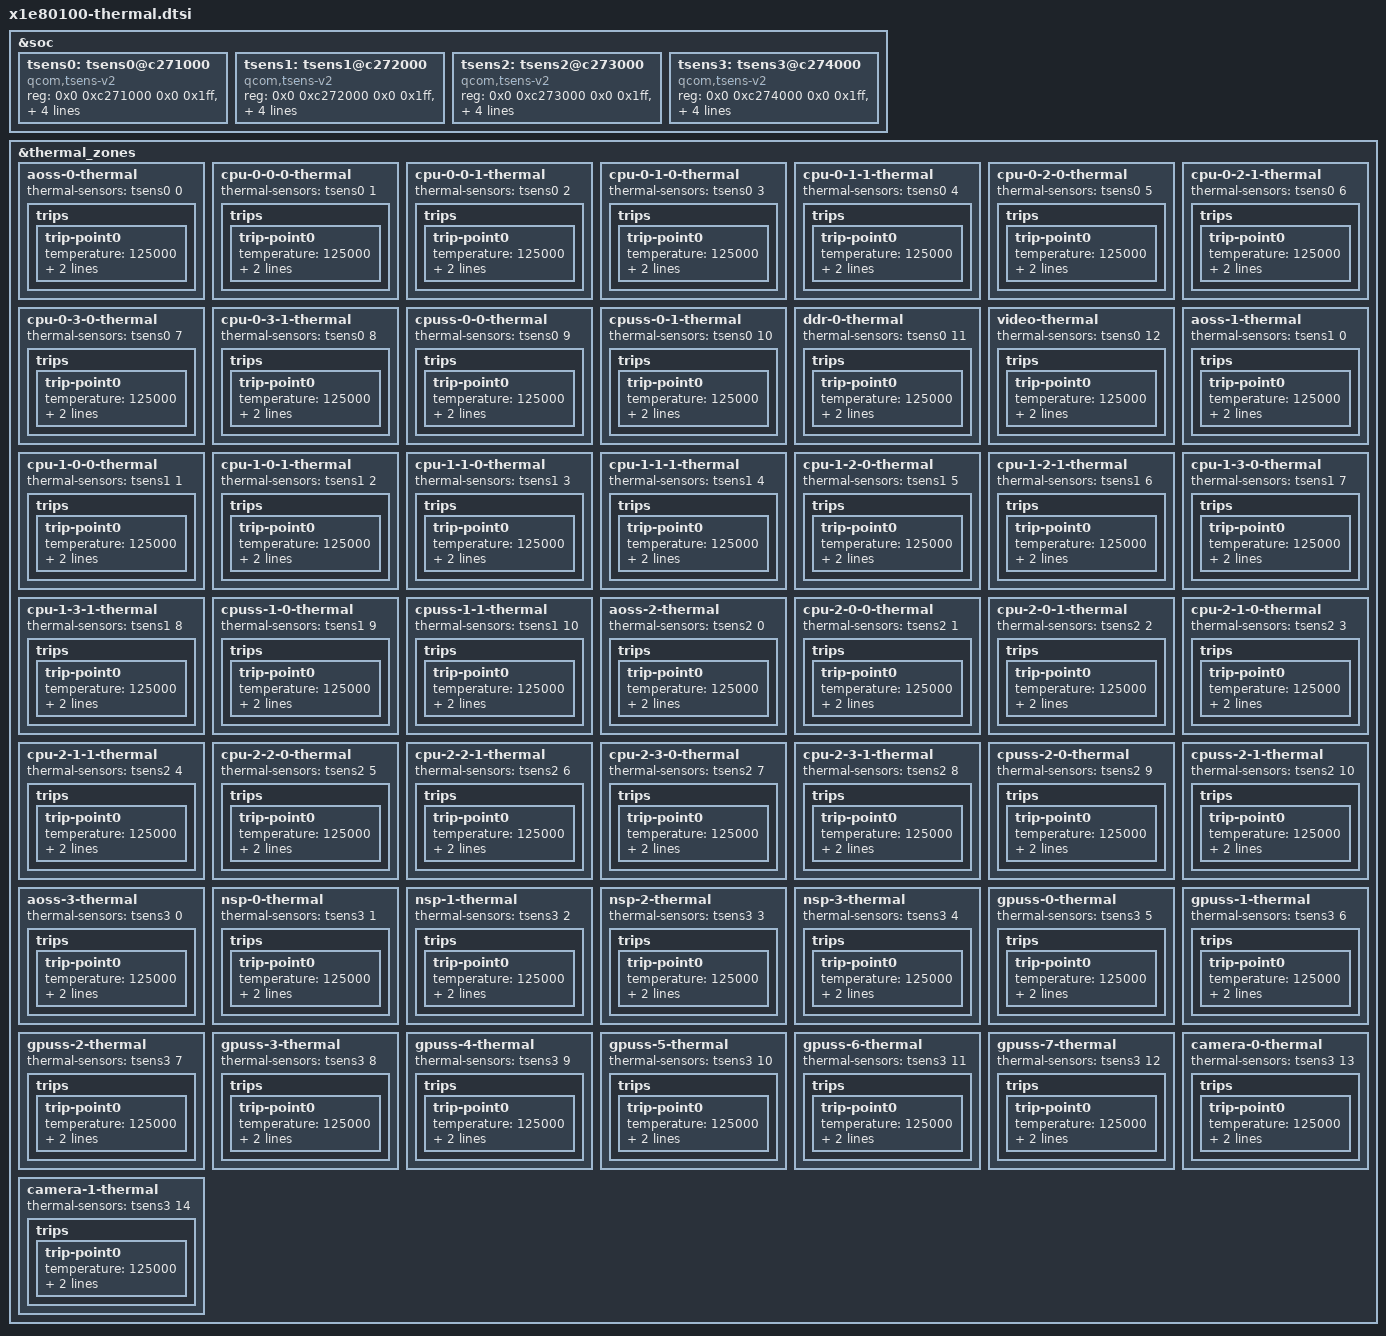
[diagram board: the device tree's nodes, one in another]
// SPDX-License-Identifier: BSD-3-Clause
/*
 * Copyright (c) Qualcomm Technologies, Inc. and/or its subsidiaries.
 */

#include <dt-bindings/thermal/thermal_qti.h>

&soc {
	tsens0: tsens0@c271000 {
		compatible = "qcom,tsens-v2";
		reg = <0x0 0xc271000 0x0 0x1ff>, /* TM */
				<0x0 0xc222000 0x0 0x1ff>; /* SROT */
		#qcom,sensors = <13>;
		interrupts = <GIC_SPI 506 IRQ_TYPE_LEVEL_HIGH>,
				<GIC_SPI 641 IRQ_TYPE_LEVEL_HIGH>;
		interrupt-names = "uplow","critical";
		#thermal-sensor-cells = <1>;
	};

	tsens1: tsens1@c272000 {
		compatible = "qcom,tsens-v2";
		reg = <0x0 0xc272000 0x0 0x1ff>, /* TM */
				<0x0 0xc223000 0x0 0x1ff>; /* SROT */
		#qcom,sensors = <11>;
		interrupts = <GIC_SPI 507 IRQ_TYPE_LEVEL_HIGH>,
				<GIC_SPI 642 IRQ_TYPE_LEVEL_HIGH>;
		interrupt-names = "uplow","critical";
		#thermal-sensor-cells = <1>;
	};

	tsens2: tsens2@c273000 {
		compatible = "qcom,tsens-v2";
		reg = <0x0 0xc273000 0x0 0x1ff>, /* TM */
				<0x0 0xc224000 0x0 0x1ff>; /* SROT */
		#qcom,sensors = <11>;
		interrupts = <GIC_SPI 508 IRQ_TYPE_LEVEL_HIGH>,
				<GIC_SPI 643 IRQ_TYPE_LEVEL_HIGH>;
		interrupt-names = "uplow","critical";
		#thermal-sensor-cells = <1>;
	};

	tsens3: tsens3@c274000 {
		compatible = "qcom,tsens-v2";
		reg = <0x0 0xc274000 0x0 0x1ff>, /* TM */
				<0x0 0xc225000 0x0 0x1ff>; /* SROT */
		#qcom,sensors = <15>;
		interrupts = <GIC_SPI 509 IRQ_TYPE_LEVEL_HIGH>,
				<GIC_SPI 644 IRQ_TYPE_LEVEL_HIGH>;
		interrupt-names = "uplow","critical";
		#thermal-sensor-cells = <1>;
	};
};

&thermal_zones {
	aoss-0-thermal {
		thermal-sensors = <&tsens0 0>;
		trips {
			trip-point0 {
				temperature = <125000>;
				hysteresis = <5000>;
				type = "passive";
			};
		};
	};

	cpu-0-0-0-thermal {
		thermal-sensors = <&tsens0 1>;
		trips {
			trip-point0 {
				temperature = <125000>;
				hysteresis = <5000>;
				type = "passive";
			};
		};
	};

	cpu-0-0-1-thermal {
		thermal-sensors = <&tsens0 2>;
		trips {
			trip-point0 {
				temperature = <125000>;
				hysteresis = <5000>;
				type = "passive";
			};
		};
	};

	cpu-0-1-0-thermal {
		thermal-sensors = <&tsens0 3>;
		trips {
			trip-point0 {
				temperature = <125000>;
				hysteresis = <5000>;
				type = "passive";
			};
		};
	};

	cpu-0-1-1-thermal {
		thermal-sensors = <&tsens0 4>;
		trips {
			trip-point0 {
				temperature = <125000>;
				hysteresis = <5000>;
				type = "passive";
			};
		};
	};

	cpu-0-2-0-thermal {
		thermal-sensors = <&tsens0 5>;
		trips {
			trip-point0 {
				temperature = <125000>;
				hysteresis = <5000>;
				type = "passive";
			};
		};
	};

	cpu-0-2-1-thermal {
		thermal-sensors = <&tsens0 6>;
		trips {
			trip-point0 {
				temperature = <125000>;
				hysteresis = <5000>;
				type = "passive";
			};
		};
	};

	cpu-0-3-0-thermal {
		thermal-sensors = <&tsens0 7>;
		trips {
			trip-point0 {
				temperature = <125000>;
				hysteresis = <5000>;
				type = "passive";
			};
		};
	};

	cpu-0-3-1-thermal {
		thermal-sensors = <&tsens0 8>;
		trips {
			trip-point0 {
				temperature = <125000>;
				hysteresis = <5000>;
				type = "passive";
			};
		};
	};

	cpuss-0-0-thermal {
		thermal-sensors = <&tsens0 9>;
		trips {
			trip-point0 {
				temperature = <125000>;
				hysteresis = <5000>;
				type = "passive";
			};
		};
	};

	cpuss-0-1-thermal {
		thermal-sensors = <&tsens0 10>;
		trips {
			trip-point0 {
				temperature = <125000>;
				hysteresis = <5000>;
				type = "passive";
			};
		};
	};

	ddr-0-thermal {
		thermal-sensors = <&tsens0 11>;
		trips {
			trip-point0 {
				temperature = <125000>;
				hysteresis = <5000>;
				type = "passive";
			};
		};
	};

	video-thermal {
		thermal-sensors = <&tsens0 12>;
		trips {
			trip-point0 {
				temperature = <125000>;
				hysteresis = <5000>;
				type = "passive";
			};
		};
	};

	aoss-1-thermal {
		thermal-sensors = <&tsens1 0>;
		trips {
			trip-point0 {
				temperature = <125000>;
				hysteresis = <5000>;
				type = "passive";
			};
		};
	};

	cpu-1-0-0-thermal {
		thermal-sensors = <&tsens1 1>;
		trips {
			trip-point0 {
				temperature = <125000>;
				hysteresis = <5000>;
				type = "passive";
			};
		};
	};

	cpu-1-0-1-thermal {
		thermal-sensors = <&tsens1 2>;
		trips {
			trip-point0 {
				temperature = <125000>;
				hysteresis = <5000>;
				type = "passive";
			};
		};
	};

	cpu-1-1-0-thermal {
		thermal-sensors = <&tsens1 3>;
		trips {
			trip-point0 {
				temperature = <125000>;
				hysteresis = <5000>;
				type = "passive";
			};
		};
	};

	cpu-1-1-1-thermal {
		thermal-sensors = <&tsens1 4>;
		trips {
			trip-point0 {
				temperature = <125000>;
				hysteresis = <5000>;
				type = "passive";
			};
		};
	};

	cpu-1-2-0-thermal {
		thermal-sensors = <&tsens1 5>;
		trips {
			trip-point0 {
				temperature = <125000>;
				hysteresis = <5000>;
				type = "passive";
			};
		};
	};

	cpu-1-2-1-thermal {
		thermal-sensors = <&tsens1 6>;
		trips {
			trip-point0 {
				temperature = <125000>;
				hysteresis = <5000>;
				type = "passive";
			};
		};
	};

	cpu-1-3-0-thermal {
		thermal-sensors = <&tsens1 7>;
		trips {
			trip-point0 {
				temperature = <125000>;
				hysteresis = <5000>;
				type = "passive";
			};
		};
	};

	cpu-1-3-1-thermal {
		thermal-sensors = <&tsens1 8>;
		trips {
			trip-point0 {
				temperature = <125000>;
				hysteresis = <5000>;
				type = "passive";
			};
		};
	};

	cpuss-1-0-thermal {
		thermal-sensors = <&tsens1 9>;
		trips {
			trip-point0 {
				temperature = <125000>;
				hysteresis = <5000>;
				type = "passive";
			};
		};
	};

	cpuss-1-1-thermal {
		thermal-sensors = <&tsens1 10>;
		trips {
			trip-point0 {
				temperature = <125000>;
				hysteresis = <5000>;
				type = "passive";
			};
		};
	};

	aoss-2-thermal {
		thermal-sensors = <&tsens2 0>;
		trips {
			trip-point0 {
				temperature = <125000>;
				hysteresis = <5000>;
				type = "passive";
			};
		};
	};

	cpu-2-0-0-thermal {
		thermal-sensors = <&tsens2 1>;
		trips {
			trip-point0 {
				temperature = <125000>;
				hysteresis = <5000>;
				type = "passive";
			};
		};
	};

	cpu-2-0-1-thermal {
		thermal-sensors = <&tsens2 2>;
		trips {
			trip-point0 {
				temperature = <125000>;
				hysteresis = <5000>;
				type = "passive";
			};
		};
	};

	cpu-2-1-0-thermal {
		thermal-sensors = <&tsens2 3>;
		trips {
			trip-point0 {
				temperature = <125000>;
				hysteresis = <5000>;
				type = "passive";
			};
		};
	};

	cpu-2-1-1-thermal {
		thermal-sensors = <&tsens2 4>;
		trips {
			trip-point0 {
				temperature = <125000>;
				hysteresis = <5000>;
				type = "passive";
			};
		};
	};

	cpu-2-2-0-thermal {
		thermal-sensors = <&tsens2 5>;
		trips {
			trip-point0 {
				temperature = <125000>;
				hysteresis = <5000>;
				type = "passive";
			};
		};
	};

	cpu-2-2-1-thermal {
		thermal-sensors = <&tsens2 6>;
		trips {
			trip-point0 {
				temperature = <125000>;
				hysteresis = <5000>;
				type = "passive";
			};
		};
	};

	cpu-2-3-0-thermal {
		thermal-sensors = <&tsens2 7>;
		trips {
			trip-point0 {
				temperature = <125000>;
				hysteresis = <5000>;
				type = "passive";
			};
		};
	};

	cpu-2-3-1-thermal {
		thermal-sensors = <&tsens2 8>;
		trips {
			trip-point0 {
				temperature = <125000>;
				hysteresis = <5000>;
				type = "passive";
			};
		};
	};

	cpuss-2-0-thermal {
		thermal-sensors = <&tsens2 9>;
		trips {
			trip-point0 {
				temperature = <125000>;
				hysteresis = <5000>;
				type = "passive";
			};
		};
	};

	cpuss-2-1-thermal {
		thermal-sensors = <&tsens2 10>;
		trips {
			trip-point0 {
				temperature = <125000>;
				hysteresis = <5000>;
				type = "passive";
			};
		};
	};

	aoss-3-thermal {
		thermal-sensors = <&tsens3 0>;
		trips {
			trip-point0 {
				temperature = <125000>;
				hysteresis = <5000>;
				type = "passive";
			};
		};
	};

	nsp-0-thermal {
		thermal-sensors = <&tsens3 1>;
		trips {
			trip-point0 {
				temperature = <125000>;
				hysteresis = <5000>;
				type = "passive";
			};
		};
	};

	nsp-1-thermal {
		thermal-sensors = <&tsens3 2>;
		trips {
			trip-point0 {
				temperature = <125000>;
				hysteresis = <5000>;
				type = "passive";
			};
		};
	};

	nsp-2-thermal {
		thermal-sensors = <&tsens3 3>;
		trips {
			trip-point0 {
				temperature = <125000>;
				hysteresis = <5000>;
				type = "passive";
			};
		};
	};

	nsp-3-thermal {
		thermal-sensors = <&tsens3 4>;
		trips {
			trip-point0 {
				temperature = <125000>;
				hysteresis = <5000>;
				type = "passive";
			};
		};
	};

	gpuss-0-thermal {
		thermal-sensors = <&tsens3 5>;
		trips {
			trip-point0 {
				temperature = <125000>;
				hysteresis = <5000>;
				type = "passive";
			};
		};
	};

	gpuss-1-thermal {
		thermal-sensors = <&tsens3 6>;
		trips {
			trip-point0 {
				temperature = <125000>;
				hysteresis = <5000>;
				type = "passive";
			};
		};
	};

	gpuss-2-thermal {
		thermal-sensors = <&tsens3 7>;
		trips {
			trip-point0 {
				temperature = <125000>;
				hysteresis = <5000>;
				type = "passive";
			};
		};
	};

	gpuss-3-thermal {
		thermal-sensors = <&tsens3 8>;
		trips {
			trip-point0 {
				temperature = <125000>;
				hysteresis = <5000>;
				type = "passive";
			};
		};
	};

	gpuss-4-thermal {
		thermal-sensors = <&tsens3 9>;
		trips {
			trip-point0 {
				temperature = <125000>;
				hysteresis = <5000>;
				type = "passive";
			};
		};
	};

	gpuss-5-thermal {
		thermal-sensors = <&tsens3 10>;
		trips {
			trip-point0 {
				temperature = <125000>;
				hysteresis = <5000>;
				type = "passive";
			};
		};
	};

	gpuss-6-thermal {
		thermal-sensors = <&tsens3 11>;
		trips {
			trip-point0 {
				temperature = <125000>;
				hysteresis = <5000>;
				type = "passive";
			};
		};
	};

	gpuss-7-thermal {
		thermal-sensors = <&tsens3 12>;
		trips {
			trip-point0 {
				temperature = <125000>;
				hysteresis = <5000>;
				type = "passive";
			};
		};
	};

	camera-0-thermal {
		thermal-sensors = <&tsens3 13>;
		trips {
			trip-point0 {
				temperature = <125000>;
				hysteresis = <5000>;
				type = "passive";
			};
		};
	};

	camera-1-thermal {
		thermal-sensors = <&tsens3 14>;
		trips {
			trip-point0 {
				temperature = <125000>;
				hysteresis = <5000>;
				type = "passive";
			};
		};
	};
};
